# D1H register map
Vendor: Allwinner; File version: 1.0
Registers are 32-bit, read-write, reset 0x0 unless marked. A register's access mark holds for its fields unless they carry their own. Offsets are from the block's base; [hi:lo] are bit positions; {n}, {i} and the like mark numbered series; 'fields as' and 'values as' point back to an identical list.

## TCON_TV0 — Timing COntroller TV
Base 0x05470000
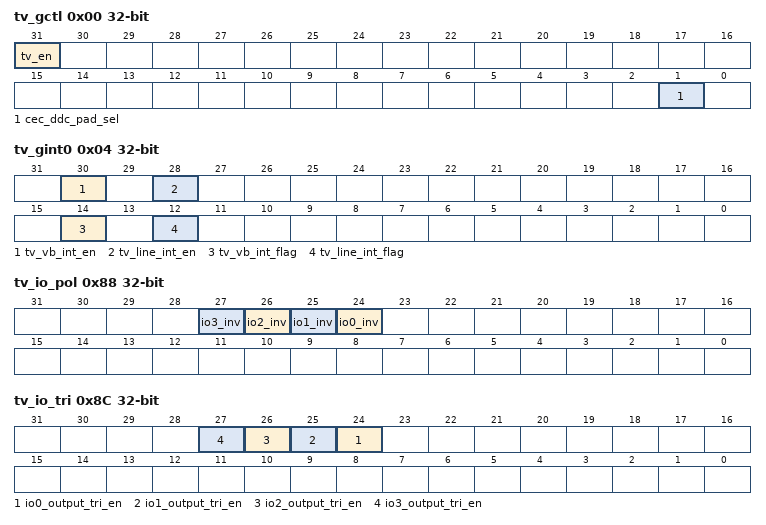
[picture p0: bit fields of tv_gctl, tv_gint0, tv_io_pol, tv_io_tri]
0x00 tv_gctl — TV Global Control Register
  [31] tv_en — When it is disabled, the module will be reset to idle state.
    0=DISABLE; 1=ENABLE
  [1] cec_ddc_pad_sel — CEC DDC PAD Select
    1=INTERNAL_PAD (TCON_TV internal pad for cec scl sal); 0=GPIO_PAD (GPIO pad for cec scl sal)
0x04 tv_gint0 — TV Global Interrupt Register0
  [30] tv_vb_int_en — TV Vb Interrupt Enable
    0=DISABLE; 1=ENABLE
  [28] tv_line_int_en — TV Line Interrupt Enable
    0=DISABLE; 1=ENABLE
  [14] tv_vb_int_flag — TV Vb Interrupt Flag . Asserted during vertical no-display period every frame. . Write 0 to clear it.
  [12] tv_line_int_flag — TV Line Interrupt Flag . Trigger when SY1 match the current TV scan line . Write 0 to clear it.
0x08 tv_gint1 — TV Global Interrupt Register1
  [11:0] tv_line_int_num — Scan line for TV line trigger(including inactive lines) . Setting it for the specified line for trigger 1. . Note: SY1 is writable only when LINE_TRG1 is disabled.
0x40 tv_src_ctl — TV Source Control Register
  [2:0] tv_src_sel — TV Source Select
    0=DE; 1=COLOR (Color Check); 2=GRAYSCALE (Grayscale Check); 3=BLACK_BY_WHITE (Black by White Check); 7=GRIDDING (Gridding Check)
0x88 tv_io_pol — TV SYNC Signal Polarity Register
  [n+24] io{n}_inv (n=0..3) — IO[i] Invert
    0=NOT_INVERT; 1=INVERT
0x8C tv_io_tri — TV SYNC Signal IO Control Register
  [n+24] io{n}_output_tri_en (n=0..3) — IO[i] Output Trigger Enable
    1=DISABLE; 0=ENABLE
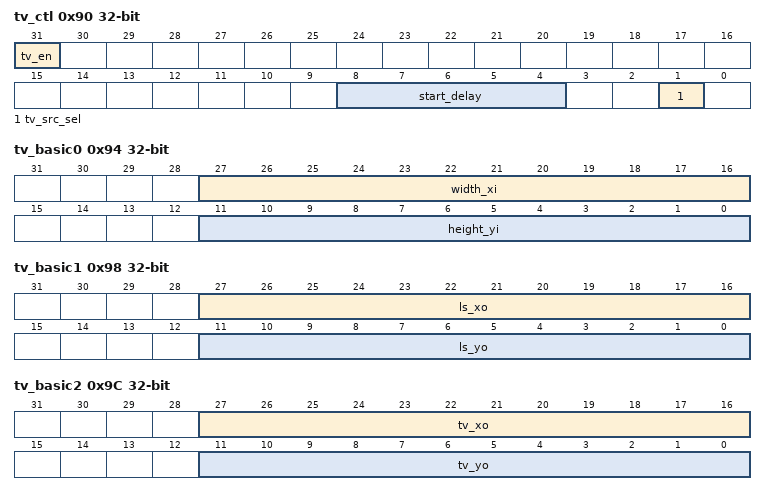
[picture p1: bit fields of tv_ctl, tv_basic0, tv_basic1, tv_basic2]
0x90 tv_ctl — TV Control Register
  [31] tv_en — When enable TCON_TV, this bit and the 0x0000[bit31] need to be enabled.
    0=DISABLE; 1=ENABLE
  [8:4] start_delay — This is for DE0 and DE1.
  [1] tv_src_sel — TV Source Select . Note: The priority of this bit is higher than TV_SRC_SEL(bit[2:0]) in TV_SRC_CTL_REG.
    1=BLUE_DATA
0x94 tv_basic0 — TV Basic Timing Register0
  [27:16] width_xi — Source Width Is X+1
  [11:0] height_yi — Source Height Is Y+1
0x98 tv_basic1 — TV Basic Timing Register1
  [27:16] ls_xo — Width Is LS_XO+1
  [11:0] ls_yo — Width Is LS_YO+1 . Note: This version LS_YO = TV_YI
0x9C tv_basic2 — TV Basic Timing Register2
  [27:16] tv_xo — Width is TV_XO+1
  [11:0] tv_yo — Height is TV_YO+1
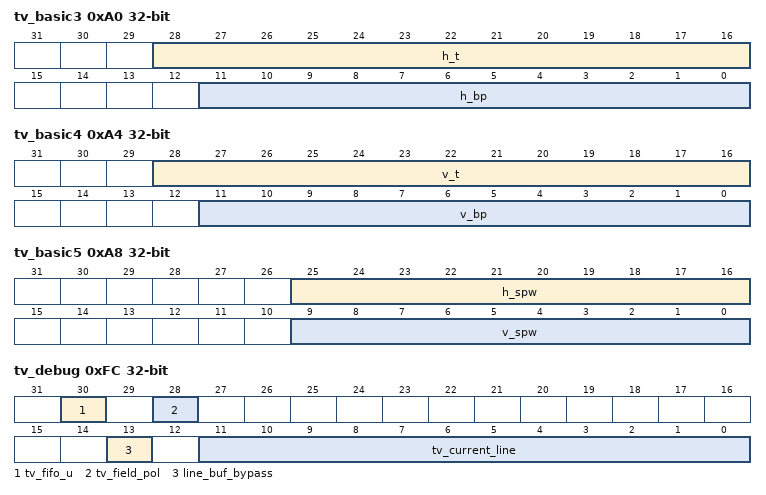
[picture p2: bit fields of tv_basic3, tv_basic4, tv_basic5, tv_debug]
0xA0 tv_basic3 — TV Basic Timing Register3
  [28:16] h_t — Horizontal total time . Thcycle = (HT+1) * Thdclk
  [11:0] h_bp — Horizontal back porch . Thbp = (HBP +1) * Thdclk
0xA4 tv_basic4 — TV Basic Timing Register4
  [28:16] v_t — horizontal total time (in HD line) . Tvt = VT/2 * Th
  [11:0] v_bp — horizontal back porch (in HD line) . Tvbp = (VBP +1) * Th
0xA8 tv_basic5 — TV Basic Timing Register5
  [25:16] h_spw — Horizontal Sync Pulse Width (in dclk) . Thspw = (HSPW+1) * Tdclk . Note: HT > (HSPW+1)
  [9:0] v_spw — Vertical Sync Pulse Width (in lines) . Tvspw = (VSPW+1) * Th . Note: VT/2 > (VSPW+1)
0xFC tv_debug
  [30] tv_fifo_u — TV FIFO Underflow
  [28] tv_field_pol ro — TV Field Polarity
    0=SECOND; 1=FIRST
  [13] line_buf_bypass — Line Buf fer Bypass
    0=U_SED; 1=BYPASS
  [11:0] tv_current_line ro
0x100 tv_ceu_ctl — TV CEU Control Register
  [31] ceu_en — CEU Enable
    0=BYPASS; 1=ENABLE
{0x110+4i} tv_ceu_coef_mul{i} (i=0..10) — TV CEU Coefficient Register0
  [8] ceu_coef_mul_value — Note: CEU_Coef_Mul_Value only can be 0 or 1.
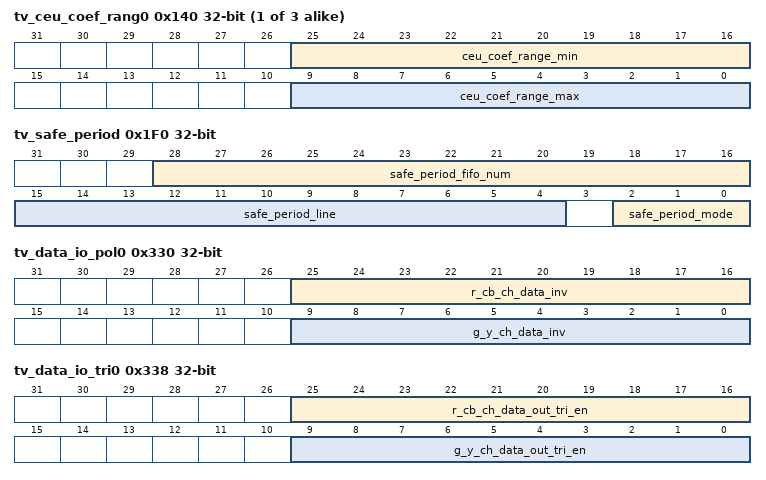
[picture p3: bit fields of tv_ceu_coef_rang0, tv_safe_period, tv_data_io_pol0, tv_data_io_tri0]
{0x140+4i} tv_ceu_coef_rang{i} (i=0..2) — TV CEU Coefficient Register2
  [25:16] ceu_coef_range_min — Unsigned 10-bit Value, range of [0, 1023]
  [9:0] ceu_coef_range_max — Unsigned 10-bit Value, range of [0, 1023]
0x1F0 tv_safe_period
  [28:16] safe_period_fifo_num — Safe Period FIFO Number
  [15:4] safe_period_line
  [2:0] safe_period_mode
    0=UNSAFE; 1=SAFE; 2=SAFE_LINE_BUF_CURR_NUM_GT_SAFE_PERIOD_FIFO_NUM (safe at LINE_BUF_CURR_NUM > SAFE_PERIOD_FIFO_NUM); 3=SAFE_2_SYNC_ACTIVE (safe at 2 and safe at sync active); 4=SAFE_LINE (safe at line)
0x300 tv_fill_ctl — TV Fill Data Control Register
  [31] tv_fill_en — TV Fill Enable
    0=BYPASS; 1=ENABLE
{0x304+0xC*i} tv_fill_begin{i} (i=0..2) — TV Fill Data Begin Register
  [23:0] fill_begin
{0x308+0xC*i} tv_fill_end{i} (i=0..2) — TV Fill Data End Register
  [23:0] fill_end
{0x30C+0xC*i} tv_fill_data{i} (i=0..2) — TV Fill Data Value Register
  [29:0] fill_value
0x330 tv_data_io_pol0 — TCON Data IO Polarity Control0
  [25:16] r_cb_ch_data_inv — R CB Channel Data Inv
    0=NORMAL (normal polarity); 1=INVERT (invert the specify output)
  [9:0] g_y_ch_data_inv — G Y Channel Data Inv
    values as r_cb_ch_data_inv
0x334 tv_data_io_pol1 — TCON Data IO Polarity Control1
  [25:16] b_cr_ch_data_inv — B CR CHANNE DATA INV
    values as tv_data_io_pol0.r_cb_ch_data_inv
0x338 tv_data_io_tri0 — TCON Data IO Enable Control0
  [25:16] r_cb_ch_data_out_tri_en — R CB Channel Data Output Trigger Enable
    0=DISABLE; 1=ENABLE
  [9:0] g_y_ch_data_out_tri_en — G Y Channel Data Output Trigger Enable
    0=DISABLE; 1=ENABLE
0x33C tv_data_io_tri1 — TCON Data IO Enable Control1
  [25:16] b_cr_ch_data_out_tri_en — B CR Channel Data Output Trigger Enable
    0=DISABLE; 1=ENABLE
0x340 tv_pixeldepth_mode — TV Pixeldepth Mode Control Register
  [0] colorbar_pd_mode — Colorbar Pixeldepth mode
    0=B_IT8 (8 bit mode . When data source is the embedded colorbar, the 8-bit colorbar pattern is transmitted.); 1=B_IT10 (10 bit mode . When data source is the embedded colorbar, the 10-bit colorbar pattern is transmitted.)
